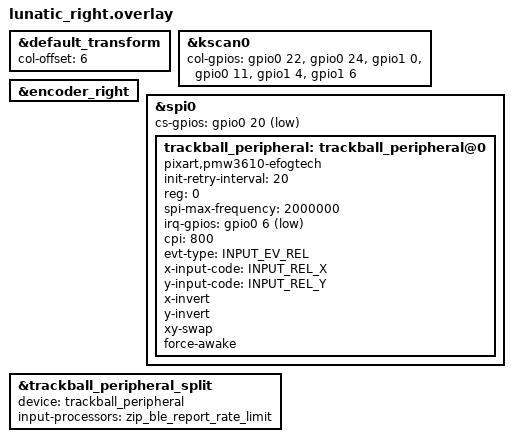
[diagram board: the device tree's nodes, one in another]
#include "lunatic.dtsi"
#include <zephyr/dt-bindings/input/input-event-codes.h>
#include <input/processors.dtsi>
#include <input/processors/xyz.dtsi>
#include <input/processors/report_rate_limit.dtsi>
#include <behaviors/rate_limit.dtsi>

#define INPUT_EV_KEY 0x01               /**< Key event */
#define INPUT_EV_REL 0x02               /**< Relative coordinate event */
#define INPUT_EV_ABS 0x03               /**< Absolute coordinate event */
#define INPUT_EV_MSC 0x04               /**< Miscellaneous event */
#define INPUT_EV_VENDOR_START 0xf0      /**< Vendor specific event start */
#define INPUT_EV_VENDOR_STOP 0xff       /**< Vendor specific event stop */

#define INPUT_REL_X 0x00                /**< Relative X coordinate */
#define INPUT_REL_Y 0x01                /**< Relative Y coordinate */
#define INPUT_REL_WHEEL 0x08            /**< Relative wheel coordinate */
#define INPUT_REL_HWHEEL 0x06           /**< Relative horizontal wheel coordinate */
#define INPUT_REL_MISC 0x09             /**< Relative misc coordinate */


&default_transform { 
    col-offset = <6>;
};

&kscan0 {
    col-gpios
            =<&gpio0 22 GPIO_ACTIVE_HIGH>, 
             <&gpio0 24 GPIO_ACTIVE_HIGH>, 
             <&gpio1 0 GPIO_ACTIVE_HIGH>,
             <&gpio0 11 GPIO_ACTIVE_HIGH>,  
             <&gpio1 4 GPIO_ACTIVE_HIGH>,
             <&gpio1 6 GPIO_ACTIVE_HIGH>
           ;  
};

&encoder_right {
    status = "okay";
};


&spi0 {

    cs-gpios = <&gpio0 20 GPIO_ACTIVE_LOW>;

    trackball_peripheral: trackball_peripheral@0 {
        status = "okay";
        compatible = "pixart,pmw3610-efogtech";
        init-retry-interval = <20>;
        reg = <0>;
        spi-max-frequency = <2000000>;
        irq-gpios = <&gpio0 6 (GPIO_ACTIVE_LOW | GPIO_PULL_UP)>;
        cpi = <800>;

        evt-type = <INPUT_EV_REL>;
        x-input-code = <INPUT_REL_X>;
        y-input-code = <INPUT_REL_Y>;
        x-invert;
        y-invert;
        xy-swap;
        force-awake;
        /* keep the sensor awake while ZMK activity state is ACTIVE,
           fallback to normal downshift mode after ZMK goes into IDLE / SLEEP mode.
           thus, the sensor would be a `wakeup-source` */
        /*   optional features   */
        /* automouse-layer = <3>; */

    };

};

&trackball_peripheral_split {
    device = <&trackball_peripheral>;
    input-processors = <&zip_ble_report_rate_limit>;
     //= <&zip_xy_to_scroll_mapper>//
     //, <&zip_xyz>//
     //, <&zip_ble_report_rate_limit>;//
};
